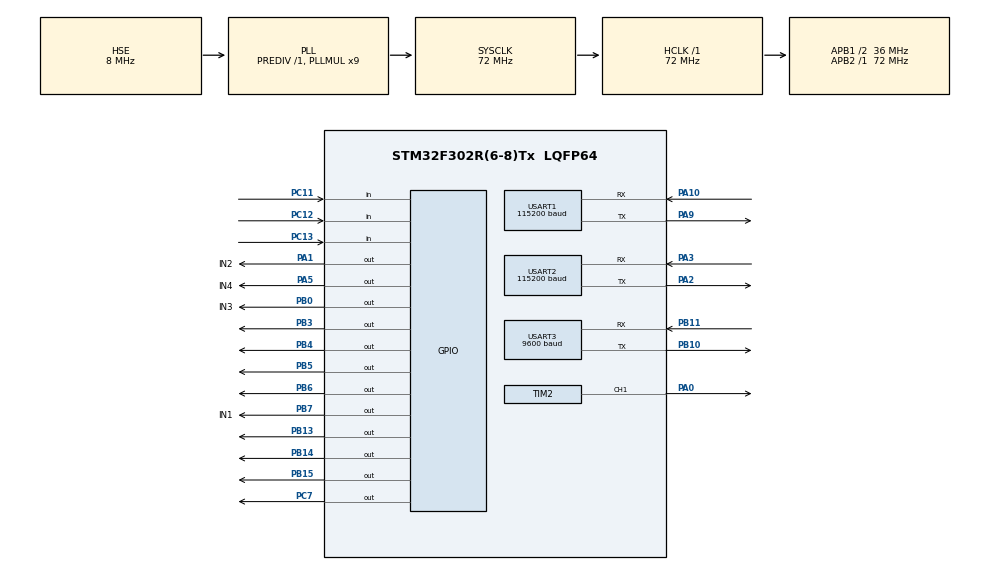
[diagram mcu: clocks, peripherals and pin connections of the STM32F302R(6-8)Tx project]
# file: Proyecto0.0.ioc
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Mcu.Family=STM32F3
Mcu.Name=STM32F302R(6-8)Tx
Mcu.Package=LQFP64
NVIC.PriorityGroup=NVIC_PRIORITYGROUP_4
NVIC.USART1_IRQn=true\:0\:0\:false\:false\:true\:true\:true\:true
NVIC.USART2_IRQn=true\:0\:0\:false\:false\:true\:true\:true\:true
PA0.Signal=S_TIM2_CH1_ETR
PA1.GPIO_Label=IN2
PA1.Signal=GPIO_Output
PA10.Mode=Asynchronous
PA10.Signal=USART1_RX
PA13.Mode=Serial_Wire
PA13.Signal=SYS_JTMS-SWDIO
PA14.Mode=Serial_Wire
PA14.Signal=SYS_JTCK-SWCLK
PA2.Mode=Asynchronous
PA2.Signal=USART2_TX
PA3.Mode=Asynchronous
PA3.Signal=USART2_RX
PA5.GPIO_Label=IN4
PA5.Signal=GPIO_Output
PA9.Mode=Asynchronous
PA9.Signal=USART1_TX
PB0.GPIO_Label=IN3
PB0.Signal=GPIO_Output
PB10.Mode=Asynchronous
PB10.Signal=USART3_TX
PB11.Mode=Asynchronous
PB11.Signal=USART3_RX
PB13.Signal=GPIO_Output
PB14.Signal=GPIO_Output
PB15.Signal=GPIO_Output
PB3.Signal=GPIO_Output
PB4.Signal=GPIO_Output
PB5.Signal=GPIO_Output
PB6.Signal=GPIO_Output
PB7.GPIO_Label=IN1
PB7.Signal=GPIO_Output
PC11.GPIO_PuPd=GPIO_PULLUP
PC11.Signal=GPIO_Input
PC12.GPIO_PuPd=GPIO_PULLUP
PC12.Signal=GPIO_Input
PC13.GPIO_PuPd=GPIO_PULLUP
PC13.Signal=GPIO_Input
PC7.Signal=GPIO_Output
PF0-OSC_IN.Mode=HSE-External-Oscillator
PF0-OSC_IN.Signal=RCC_OSC_IN
PF1-OSC_OUT.Mode=HSE-External-Oscillator
PF1-OSC_OUT.Signal=RCC_OSC_OUT
ProjectManager.HeapSize=0x200
ProjectManager.StackSize=0x400
ProjectManager.TargetToolchain=STM32CubeIDE
RCC.AHBFreq_Value=72000000
RCC.APB1CLKDivider=RCC_HCLK_DIV2
RCC.APB1Freq_Value=36000000
RCC.APB1TimFreq_Value=72000000
RCC.APB2Freq_Value=72000000
RCC.APB2TimFreq_Value=72000000
RCC.CortexFreq_Value=72000000
RCC.HCLKFreq_Value=72000000
RCC.HSE_VALUE=8000000
RCC.HSI_VALUE=8000000
RCC.LSE_VALUE=32768
RCC.PLLM=8
RCC.PLLMUL=RCC_PLL_MUL9
RCC.PLLN=336
RCC.PLLP=RCC_PLLP_DIV4
RCC.PLLQ=7
RCC.PLLSourceVirtual=RCC_PLLSOURCE_HSE
RCC.SYSCLKFreq_VALUE=72000000
RCC.SYSCLKSourceVirtual=RCC_SYSCLKSOURCE_PLLCLK
RCC.USBFreq_Value=72000000
SH.S_TIM2_CH1_ETR.0=TIM2_CH1,PWM Generation1 CH1
TIM1.Period=0xffff-1
TIM1.Prescaler=72-1
TIM15.Period=20000
TIM15.Prescaler=72-1
TIM2.Channel-PWM\ Generation1\ CH1=TIM_CHANNEL_1
TIM2.Period=20000
TIM2.Prescaler=72-1
TIM2.Pulse-PWM\ Generation1\ CH1=500
USART1.BaudRate=115200
USART1.VirtualMode-Asynchronous=VM_ASYNC
USART2.BaudRate=115200
USART2.VirtualMode-Asynchronous=VM_ASYNC
USART3.BaudRate=9600
USART3.VirtualMode-Asynchronous=VM_ASYNC
VP_TIM15_VS_ClockSourceINT.Mode=Internal
VP_TIM1_VS_ClockSourceINT.Mode=Internal
VP_TIM2_VS_ClockSourceINT.Mode=Internal
board=NUCLEO-F302R8

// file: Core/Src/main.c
/* USER CODE BEGIN Header */
/**
 ******************************************************************************
 * @file           : main.c
 * @brief          : Main program body
 ******************************************************************************
 * @attention
 *
 * Copyright (c) 2023 STMicroelectronics.
 * All rights reserved.
 *
 * This software is licensed under terms that can be found in the LICENSE file
 * in the root directory of this software component.
 * If no LICENSE file comes with this software, it is provided AS-IS.
 *
 ******************************************************************************
 ************************************************************************************************************************************************************
 ******************************************************************************
 Nombre: Angel Gabrir Segura V

 Matricula: 2021-0311

 Proyecto final
 ******************************************************************************
 ******************************************************************************
 */
/* USER CODE END Header */
#include "main.h"
/* USER CODE BEGIN Includes */
#include "ESP8266_HAL.h"
//#include "Servo.h"
//#include "StepMotor.h"
//#include "max_matrix_stm32.h"

#define SERVO_TIMER &htim2
#define SERVO_CHANNEL TIM_CHANNEL_1
/* USER CODE END Includes */

TIM_HandleTypeDef htim1;
TIM_HandleTypeDef htim2;
TIM_HandleTypeDef htim15;

UART_HandleTypeDef huart1;
UART_HandleTypeDef huart2;
UART_HandleTypeDef huart3;

void SystemClock_Config(void);
static void MX_GPIO_Init(void);
static void MX_USART2_UART_Init(void);
static void MX_USART1_UART_Init(void);
static void MX_USART3_UART_Init(void);
static void MX_TIM2_Init(void);
static void MX_TIM1_Init(void);
static void MX_TIM15_Init(void);

/* USER CODE BEGIN 0 */
/*
void delay(uint16_t us) {
	__HAL_TIM_SET_COUNTER(&htim1, 0);

	while (__HAL_TIM_GET_COUNTER(&htim1) < us)
		;
}

#define stepsperrev 4096*/

/* USER CODE END 0 */

int main(void)
{

  /* MCU Configuration--------------------------------------------------------*/

  /* Reset of all peripherals, Initializes the Flash interface and the Systick. */
  HAL_Init();

  /* USER CODE BEGIN Init */
	//Servo servo;
  /* USER CODE END Init */

  /* Configure the system clock */
  SystemClock_Config();

  /* Initialize all configured peripherals */
  MX_GPIO_Init();
  MX_USART2_UART_Init();
  MX_USART1_UART_Init();
  MX_USART3_UART_Init();
  MX_TIM2_Init();
  MX_TIM1_Init();
  MX_TIM15_Init();
  /* USER CODE BEGIN 2 */

	//HAL_TIM_Base_Start(&htim1);
	//Servo_Init(&servo, &htim2, TIM_CHANNEL_1);
	//max_init(0x02);
	//Ringbuf_init();
	ESP_Init("122222","1234567890"); //"CLAROKN9QT","485754435EBED19C"//"iPhone de jorge luis","jorge829"//el mio
//"Redmi Note 9S", "53c289b6633c"
  /* USER CODE END 2 */

  /* Infinite loop */
  while (1)
  {
	  Server_Start();
	  	/*	if (HAL_GPIO_ReadPin(GPIOB, GPIO_PIN_13) == 1) {
	  			//Servo_MoveToAngle(&servo, 180, 200);
	  			stepper_step_angle(500, 0, 13);
	  			max_clear();
	  			write_char(127, 1);
	  		} else if (HAL_GPIO_ReadPin(GPIOB, GPIO_PIN_5) == 1) {
	  			//Servo_MoveToAngle(&servo, 0, 200);
	  			//stepper_step_angle(90, 0, 13);
	  			//Send_cmd(0x0F, 0x01, 0x01);
	  			//scroll_char (27  ,200, left);
	  			//scroll_char (26  ,200, right);
	  			max_clear();
	  			write_char(128, 1);

	  		} else if (HAL_GPIO_ReadPin(GPIOB, GPIO_PIN_4) == 1) {
	  			max_clear();
	  			write_char(129, 1);

	  		} else if (HAL_GPIO_ReadPin(GPIOB, GPIO_PIN_3) == 1) {
	  			max_clear();
	  			write_char(130, 1);

	  		} else if (HAL_GPIO_ReadPin(GPIOC, GPIO_PIN_7) == 1) {
	  			max_clear();
	  			write_char(131, 1);

	  		}*/
	}
}

void SystemClock_Config(void)
{
  RCC_OscInitTypeDef RCC_OscInitStruct = {0};
  RCC_ClkInitTypeDef RCC_ClkInitStruct = {0};
  RCC_PeriphCLKInitTypeDef PeriphClkInit = {0};

  /** Initializes the RCC Oscillators according to the specified parameters
  * in the RCC_OscInitTypeDef structure.
  */
  RCC_OscInitStruct.OscillatorType = RCC_OSCILLATORTYPE_HSE;
  RCC_OscInitStruct.HSEState = RCC_HSE_ON;
  RCC_OscInitStruct.HSEPredivValue = RCC_HSE_PREDIV_DIV1;
  RCC_OscInitStruct.HSIState = RCC_HSI_ON;
  RCC_OscInitStruct.PLL.PLLState = RCC_PLL_ON;
  RCC_OscInitStruct.PLL.PLLSource = RCC_PLLSOURCE_HSE;
  RCC_OscInitStruct.PLL.PLLMUL = RCC_PLL_MUL9;
  if (HAL_RCC_OscConfig(&RCC_OscInitStruct) != HAL_OK)
  {
    Error_Handler();
  }

  /** Initializes the CPU, AHB and APB buses clocks
  */
  RCC_ClkInitStruct.ClockType = RCC_CLOCKTYPE_HCLK|RCC_CLOCKTYPE_SYSCLK
                              |RCC_CLOCKTYPE_PCLK1|RCC_CLOCKTYPE_PCLK2;
  RCC_ClkInitStruct.SYSCLKSource = RCC_SYSCLKSOURCE_PLLCLK;
  RCC_ClkInitStruct.AHBCLKDivider = RCC_SYSCLK_DIV1;
  RCC_ClkInitStruct.APB1CLKDivider = RCC_HCLK_DIV2;
  RCC_ClkInitStruct.APB2CLKDivider = RCC_HCLK_DIV1;

  if (HAL_RCC_ClockConfig(&RCC_ClkInitStruct, FLASH_LATENCY_2) != HAL_OK)
  {
    Error_Handler();
  }
  PeriphClkInit.PeriphClockSelection = RCC_PERIPHCLK_USART1|RCC_PERIPHCLK_TIM1
                              |RCC_PERIPHCLK_TIM15;
  PeriphClkInit.Usart1ClockSelection = RCC_USART1CLKSOURCE_PCLK1;
  PeriphClkInit.Tim1ClockSelection = RCC_TIM1CLK_HCLK;
  PeriphClkInit.Tim15ClockSelection = RCC_TIM15CLK_HCLK;
  if (HAL_RCCEx_PeriphCLKConfig(&PeriphClkInit) != HAL_OK)
  {
    Error_Handler();
  }
}

static void MX_TIM1_Init(void)
{

  TIM_ClockConfigTypeDef sClockSourceConfig = {0};
  TIM_MasterConfigTypeDef sMasterConfig = {0};

  htim1.Instance = TIM1;
  htim1.Init.Prescaler = 72-1;
  htim1.Init.CounterMode = TIM_COUNTERMODE_UP;
  htim1.Init.Period = 0xffff-1;
  htim1.Init.ClockDivision = TIM_CLOCKDIVISION_DIV1;
  htim1.Init.RepetitionCounter = 0;
  htim1.Init.AutoReloadPreload = TIM_AUTORELOAD_PRELOAD_DISABLE;
  if (HAL_TIM_Base_Init(&htim1) != HAL_OK)
  {
    Error_Handler();
  }
  sClockSourceConfig.ClockSource = TIM_CLOCKSOURCE_INTERNAL;
  if (HAL_TIM_ConfigClockSource(&htim1, &sClockSourceConfig) != HAL_OK)
  {
    Error_Handler();
  }
  sMasterConfig.MasterOutputTrigger = TIM_TRGO_RESET;
  sMasterConfig.MasterOutputTrigger2 = TIM_TRGO2_RESET;
  sMasterConfig.MasterSlaveMode = TIM_MASTERSLAVEMODE_DISABLE;
  if (HAL_TIMEx_MasterConfigSynchronization(&htim1, &sMasterConfig) != HAL_OK)
  {
    Error_Handler();
  }

}

static void MX_TIM2_Init(void)
{

  TIM_ClockConfigTypeDef sClockSourceConfig = {0};
  TIM_MasterConfigTypeDef sMasterConfig = {0};
  TIM_OC_InitTypeDef sConfigOC = {0};

  htim2.Instance = TIM2;
  htim2.Init.Prescaler = 72-1;
  htim2.Init.CounterMode = TIM_COUNTERMODE_UP;
  htim2.Init.Period = 20000;
  htim2.Init.ClockDivision = TIM_CLOCKDIVISION_DIV1;
  htim2.Init.AutoReloadPreload = TIM_AUTORELOAD_PRELOAD_DISABLE;
  if (HAL_TIM_Base_Init(&htim2) != HAL_OK)
  {
    Error_Handler();
  }
  sClockSourceConfig.ClockSource = TIM_CLOCKSOURCE_INTERNAL;
  if (HAL_TIM_ConfigClockSource(&htim2, &sClockSourceConfig) != HAL_OK)
  {
    Error_Handler();
  }
  if (HAL_TIM_PWM_Init(&htim2) != HAL_OK)
  {
    Error_Handler();
  }
  sMasterConfig.MasterOutputTrigger = TIM_TRGO_RESET;
  sMasterConfig.MasterSlaveMode = TIM_MASTERSLAVEMODE_DISABLE;
  if (HAL_TIMEx_MasterConfigSynchronization(&htim2, &sMasterConfig) != HAL_OK)
  {
    Error_Handler();
  }
  sConfigOC.OCMode = TIM_OCMODE_PWM1;
  sConfigOC.Pulse = 500;
  sConfigOC.OCPolarity = TIM_OCPOLARITY_HIGH;
  sConfigOC.OCFastMode = TIM_OCFAST_DISABLE;
  if (HAL_TIM_PWM_ConfigChannel(&htim2, &sConfigOC, TIM_CHANNEL_1) != HAL_OK)
  {
    Error_Handler();
  }
  HAL_TIM_MspPostInit(&htim2);

}

static void MX_TIM15_Init(void)
{

  TIM_ClockConfigTypeDef sClockSourceConfig = {0};
  TIM_MasterConfigTypeDef sMasterConfig = {0};

  htim15.Instance = TIM15;
  htim15.Init.Prescaler = 72-1;
  htim15.Init.CounterMode = TIM_COUNTERMODE_UP;
  htim15.Init.Period = 20000;
  htim15.Init.ClockDivision = TIM_CLOCKDIVISION_DIV1;
  htim15.Init.RepetitionCounter = 0;
  htim15.Init.AutoReloadPreload = TIM_AUTORELOAD_PRELOAD_DISABLE;
  if (HAL_TIM_Base_Init(&htim15) != HAL_OK)
  {
    Error_Handler();
  }
  sClockSourceConfig.ClockSource = TIM_CLOCKSOURCE_INTERNAL;
  if (HAL_TIM_ConfigClockSource(&htim15, &sClockSourceConfig) != HAL_OK)
  {
    Error_Handler();
  }
  sMasterConfig.MasterOutputTrigger = TIM_TRGO_RESET;
  sMasterConfig.MasterSlaveMode = TIM_MASTERSLAVEMODE_DISABLE;
  if (HAL_TIMEx_MasterConfigSynchronization(&htim15, &sMasterConfig) != HAL_OK)
  {
    Error_Handler();
  }

}

static void MX_USART1_UART_Init(void)
{

  huart1.Instance = USART1;
  huart1.Init.BaudRate = 115200;
  huart1.Init.WordLength = UART_WORDLENGTH_8B;
  huart1.Init.StopBits = UART_STOPBITS_1;
  huart1.Init.Parity = UART_PARITY_NONE;
  huart1.Init.Mode = UART_MODE_TX_RX;
  huart1.Init.HwFlowCtl = UART_HWCONTROL_NONE;
  huart1.Init.OverSampling = UART_OVERSAMPLING_16;
  huart1.Init.OneBitSampling = UART_ONE_BIT_SAMPLE_DISABLE;
  huart1.AdvancedInit.AdvFeatureInit = UART_ADVFEATURE_NO_INIT;
  if (HAL_UART_Init(&huart1) != HAL_OK)
  {
    Error_Handler();
  }

}

static void MX_USART2_UART_Init(void)
{

  huart2.Instance = USART2;
  huart2.Init.BaudRate = 115200;
  huart2.Init.WordLength = UART_WORDLENGTH_8B;
  huart2.Init.StopBits = UART_STOPBITS_1;
  huart2.Init.Parity = UART_PARITY_NONE;
  huart2.Init.Mode = UART_MODE_TX_RX;
  huart2.Init.HwFlowCtl = UART_HWCONTROL_NONE;
  huart2.Init.OverSampling = UART_OVERSAMPLING_16;
  huart2.Init.OneBitSampling = UART_ONE_BIT_SAMPLE_DISABLE;
  huart2.AdvancedInit.AdvFeatureInit = UART_ADVFEATURE_NO_INIT;
  if (HAL_UART_Init(&huart2) != HAL_OK)
  {
    Error_Handler();
  }

}

static void MX_USART3_UART_Init(void)
{

  huart3.Instance = USART3;
  huart3.Init.BaudRate = 9600;
  huart3.Init.WordLength = UART_WORDLENGTH_8B;
  huart3.Init.StopBits = UART_STOPBITS_1;
  huart3.Init.Parity = UART_PARITY_NONE;
  huart3.Init.Mode = UART_MODE_TX_RX;
  huart3.Init.HwFlowCtl = UART_HWCONTROL_NONE;
  huart3.Init.OverSampling = UART_OVERSAMPLING_16;
  huart3.Init.OneBitSampling = UART_ONE_BIT_SAMPLE_DISABLE;
  huart3.AdvancedInit.AdvFeatureInit = UART_ADVFEATURE_NO_INIT;
  if (HAL_UART_Init(&huart3) != HAL_OK)
  {
    Error_Handler();
  }

}

static void MX_GPIO_Init(void)
{
  GPIO_InitTypeDef GPIO_InitStruct = {0};

  /* GPIO Ports Clock Enable */
  __HAL_RCC_GPIOC_CLK_ENABLE();
  __HAL_RCC_GPIOF_CLK_ENABLE();
  __HAL_RCC_GPIOA_CLK_ENABLE();
  __HAL_RCC_GPIOB_CLK_ENABLE();

  /*Configure GPIO pin Output Level */
  HAL_GPIO_WritePin(GPIOA, IN2_Pin|IN4_Pin, GPIO_PIN_RESET);

  /*Configure GPIO pin Output Level */
  HAL_GPIO_WritePin(GPIOB, IN3_Pin|GPIO_PIN_13|GPIO_PIN_14|GPIO_PIN_15
                          |GPIO_PIN_3|GPIO_PIN_4|GPIO_PIN_5|GPIO_PIN_6
                          |IN1_Pin, GPIO_PIN_RESET);

  /*Configure GPIO pin Output Level */
  HAL_GPIO_WritePin(GPIOC, GPIO_PIN_7, GPIO_PIN_RESET);

  /*Configure GPIO pins : PC13 PC11 PC12 */
  GPIO_InitStruct.Pin = GPIO_PIN_13|GPIO_PIN_11|GPIO_PIN_12;
  GPIO_InitStruct.Mode = GPIO_MODE_INPUT;
  GPIO_InitStruct.Pull = GPIO_PULLUP;
  HAL_GPIO_Init(GPIOC, &GPIO_InitStruct);

  /*Configure GPIO pins : IN2_Pin IN4_Pin */
  GPIO_InitStruct.Pin = IN2_Pin|IN4_Pin;
  GPIO_InitStruct.Mode = GPIO_MODE_OUTPUT_PP;
  GPIO_InitStruct.Pull = GPIO_NOPULL;
  GPIO_InitStruct.Speed = GPIO_SPEED_FREQ_LOW;
  HAL_GPIO_Init(GPIOA, &GPIO_InitStruct);

  /*Configure GPIO pins : IN3_Pin PB13 PB14 PB15
                           PB3 PB4 PB5 PB6
                           IN1_Pin */
  GPIO_InitStruct.Pin = IN3_Pin|GPIO_PIN_13|GPIO_PIN_14|GPIO_PIN_15
                          |GPIO_PIN_3|GPIO_PIN_4|GPIO_PIN_5|GPIO_PIN_6
                          |IN1_Pin;
  GPIO_InitStruct.Mode = GPIO_MODE_OUTPUT_PP;
  GPIO_InitStruct.Pull = GPIO_NOPULL;
  GPIO_InitStruct.Speed = GPIO_SPEED_FREQ_LOW;
  HAL_GPIO_Init(GPIOB, &GPIO_InitStruct);

  /*Configure GPIO pin : PC7 */
  GPIO_InitStruct.Pin = GPIO_PIN_7;
  GPIO_InitStruct.Mode = GPIO_MODE_OUTPUT_PP;
  GPIO_InitStruct.Pull = GPIO_NOPULL;
  GPIO_InitStruct.Speed = GPIO_SPEED_FREQ_LOW;
  HAL_GPIO_Init(GPIOC, &GPIO_InitStruct);

}

void Error_Handler(void)
{
	__disable_irq();
	while (1) {
	}
}
